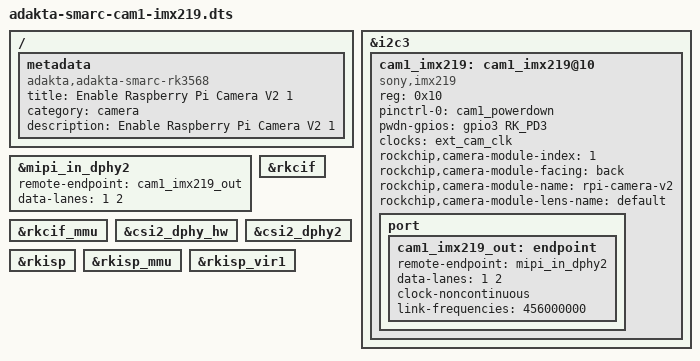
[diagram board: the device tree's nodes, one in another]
/dts-v1/;
/plugin/;

#include <dt-bindings/clock/rk3568-cru.h>
#include <dt-bindings/power/rk3568-power.h>
#include <dt-bindings/gpio/gpio.h>
#include <dt-bindings/pinctrl/rockchip.h>

/ {
	metadata {
		title = "Enable Raspberry Pi Camera V2 1";
		compatible = "adakta,adakta-smarc-rk3568";
		category = "camera";
		description = "Enable Raspberry Pi Camera V2 1";
	};

	fragment@0 {
		target = <&i2c3>;

		__overlay__ {
			status = "okay";

			cam1_imx219: cam1_imx219@10 {
				status = "okay";

				compatible = "sony,imx219";
				reg = <0x10>;

				pinctrl-names = "default";
				pinctrl-0 = <&cam1_powerdown>;

				pwdn-gpios = <&gpio3 RK_PD3 GPIO_ACTIVE_HIGH>;

				clocks = <&ext_cam_clk>;
				clock-names = "xvclk";

				rockchip,camera-module-index = <1>;
				rockchip,camera-module-facing = "back";
				rockchip,camera-module-name = "rpi-camera-v2";
				rockchip,camera-module-lens-name = "default";

				port {
					cam1_imx219_out: endpoint {
						status = "okay";
						remote-endpoint = <&mipi_in_dphy2>;
						data-lanes = <1 2>;
						clock-noncontinuous;
						link-frequencies = /bits/ 64 <456000000>;
					};
				};
			};
		};
	};

	fragment@1 {
		target = <&mipi_in_dphy2>;

		__overlay__ {
			remote-endpoint = <&cam1_imx219_out>;
			data-lanes = <1 2>;
		};
	};

	fragment@2 {
		target = <&rkcif>;

		__overlay__ {
			status = "okay";
		};
	};

	fragment@3 {
		target = <&rkcif_mmu>;

		__overlay__ {
			status = "okay";
		};
	};

	fragment@4 {
		target = <&csi2_dphy_hw>;

		__overlay__ {
			status = "okay";
		};
	};

	fragment@5 {
		target = <&csi2_dphy2>;

		__overlay__ {
			status = "okay";
		};
	};

	fragment@6 {
		target = <&rkisp>;

		__overlay__ {
			status = "okay";
		};
	};

	fragment@7 {
		target = <&rkisp_mmu>;

		__overlay__ {
			status = "okay";
		};
	};

	fragment@8 {
		target = <&rkisp_vir1>;

		__overlay__ {
			status = "okay";
		};
	};
};
